# V32F20x_CM33 register map
File version: 1.0.3
CPU: CM33 r0p4, little endian, MPU, FPU, DSP, 3 interrupt priority bits, 8 SAU regions
Registers are 32-bit, read-write, reset 0x0 unless marked. A register's access mark holds for its fields unless they carry their own. Offsets are from the block's base; [hi:lo] are bit positions; {n}, {i} and the like mark numbered series.

## DMA0 — DMA0 Peripheral Interface
Base 0x20201000
Same registers: DMA1 0x20201800, SEC_DMA0 0x30201000, SEC_DMA1 0x30201800
{0x0+0x58*i} C{i}SAR (i=0..7) — Source Address for Channel x
  [31:0] SAR — Updated after each source transfer
{0x8+0x58*i} C{i}DAR (i=0..7) — Destination Address Register for Channel x
  [31:0] DAR — Updated after each destination transfer
{0x10+0x58*i} C{i}LLP (i=0..7) — Linked List Pointer Register for Channel x
  [31:2] LOC — Starting Address In Memory of next LLI if block chaining is enabled
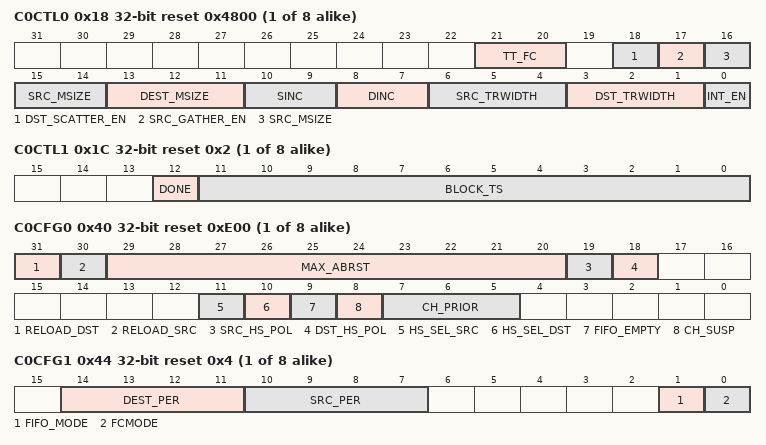
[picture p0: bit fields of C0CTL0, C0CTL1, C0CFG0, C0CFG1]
{0x18+0x58*i} C{i}CTL0 wo reset 0x4800 (i=0..7) — Control Register 0 for Channel x
  [21:20] TT_FC — Flow control can be assigned to the DMA the source peripheral or the destination peripheral
  [18] DST_SCATTER_EN — Scatter on the destination side is applicable only when the CTLx
  [17] SRC_GATHER_EN — Gather on the source side is applicable only when the CTLx
  [16:14] SRC_MSIZE — Number of data items each of width CTLx
  [13:11] DEST_MSIZE — Number of data items each of width CTLx
  [10:9] SINC — Indicates whether to increment or decrement the source address on every source transfer
  [8:7] DINC — Indicates whether to increment or decrement the destination address on every destination transfer
  [6:4] SRC_TRWIDTH — Mapped to AHB bus hsize
  [3:1] DST_TRWIDTH — Mapped to AHB bus hsize
  [0] INT_EN — If set then all interrupt generating sources are enabled
{0x1C+0x58*i} C{i}CTL1 reset 0x2 (i=0..7) — Control Register 1 for Channel x
  [12] DONE — If status write back is enabled the upper word of the control register CTL1 31 0 is written to the control register location of the Linked List Item LLI in system memory at the end of the block transfer with the done bit set
  [11:0] BLOCK_TS — When the DMA is the flow controller the user writes this field before the channel is enabled in order to indicate the block size
{0x40+0x58*i} C{i}CFG0 reset 0xE00 (i=0..7) — Configuration Register 0 for Channel x
  [31] RELOAD_DST — The DARx register can be automatically reloaded from its initial value at the end of every block for multi block transfers
  [30] RELOAD_SRC — The SARx register can be automatically reloaded from its initial value at the end of every block for multi block transfers
  [29:20] MAX_ABRST — Maximum AMBA burst length that is used for DMA transfers on this channel
  [19] SRC_HS_POL — 0x0 Source Handshaking Interface Polarity is Active high
  [18] DST_HS_POL — Destination Handshaking Interface Polarity.
  [11] HS_SEL_SRC — This register selects which of the handshaking interfaces
  [10] HS_SEL_DST — This register selects which of the handshaking interfaces
  [9] FIFO_EMPTY — Indicates if there is data left in the channel FIFO
  [8] CH_SUSP — Suspends all DMA data transfers from the source until this bit is cleared
  [7:5] CH_PRIOR — A priority of 7 is the highest priority and 0 is the lowest
{0x44+0x58*i} C{i}CFG1 reset 0x4 (i=0..7) — Configuration Register 1 for Channel
  [14:11] DEST_PER — Destination hardware interface.
  [10:7] SRC_PER — Source Hardware Interface
  [1] FIFO_MODE — Determines how much space or data needs to be available in the FIFO before a burst transaction request is serviced
  [0] FCMODE — Determines when source transaction requests are serviced when the Destination Peripheral is the flow controller
0x2C0 RAWTFR — Raw Status for IntTfr Interrupt
  [7:0] RAW
0x2C8 RAWBLOCK — Raw Status for IntBlock Interrupt
  [7:0] RAW
0x2D0 RAWSRCTRAN — Raw Status for IntSrcTran Interrupt
  [7:0] RAW
0x2D8 RAWDSTTRAN — Raw Status for IntDstTran Interrupt
  [7:0] RAW
0x2E0 RAWERR — Raw Status for IntErr Interrupt
  [7:0] RAW
0x2E8 STATUSTFR ro — Status for IntTfr Interrupt
  [7:0] STATUS
0x2F0 STATUSBLOCK ro — Status for Block Interrupt
  [7:0] STATUS
0x2F8 STATUSSRCTRAN ro — Status for SrcTran Interrupt
  [7:0] STATUS
0x300 STATUSDSTTRAN ro — Status for DstTran Interrupt
  [7:0] STATUS
0x308 STATUSERR ro — Status for Err Interrupt
  [7:0] STATUS
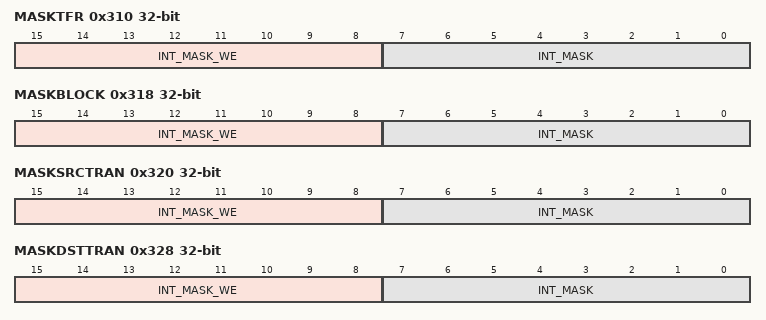
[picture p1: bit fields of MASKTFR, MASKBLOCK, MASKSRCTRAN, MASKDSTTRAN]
0x310 MASKTFR — Status for IntTfr Interrupt
  [15:8] INT_MASK_WE — Interrupt Mask Write Enable
  [7:0] INT_MASK — Mask for IntTfr Interrupt
0x318 MASKBLOCK — Status for IntBlock Interrupt
  [15:8] INT_MASK_WE — Interrupt Mask Write Enable
  [7:0] INT_MASK — Mask for IntBlock Interrupt
0x320 MASKSRCTRAN — Status for IntSrcTran Interrupt
  [15:8] INT_MASK_WE — Interrupt Mask Write Enable
  [7:0] INT_MASK — Mask for IntSrcTran Interrupt
0x328 MASKDSTTRAN — Mask for IntDstTran Interrupt
  [15:8] INT_MASK_WE — Interrupt Mask Write Enable
  [7:0] INT_MASK — Mask for IntDstTran Interrupt
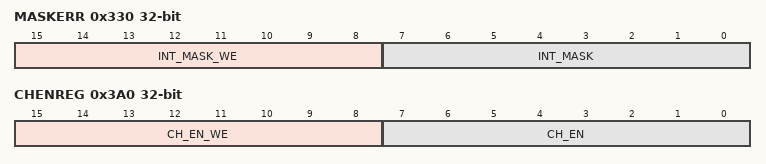
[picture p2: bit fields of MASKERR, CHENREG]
0x330 MASKERR — Mask for IntErr Interrupt
  [15:8] INT_MASK_WE — Interrupt Mask Write Enable
  [7:0] INT_MASK — Mask for IntErr Interrupt
0x338 CLEARTFR wo — Clear for IntTfr Interrupt
  [7:0] CLEAR
0x340 CLEARBLOCK wo — Clear for IntBlock Interrupt
  [7:0] CLEAR
0x348 CLEARSRCTRAN wo — Clear for IntSrcTran Interrupt
  [7:0] CLEAR
0x350 CLEARDSTTRAN wo — Clear for IntDstTran Interrupt
  [7:0] CLEAR
0x358 CLEARERR wo — Clear for IntErr Interrupt
  [7:0] CLEAR
0x398 DMACFGREG — DMAC Configuration Register
  [0] DMA_EN — DMA enable
0x3A0 CHENREG — DMAC Channel Enable Register
  [15:8] CH_EN_WE — Channel enable register
  [7:0] CH_EN — Channel Enable
